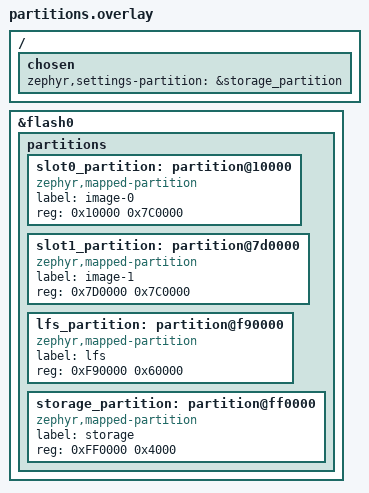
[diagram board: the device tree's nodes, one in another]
/*
 * Flash partition layout — SHARED by the app image and MCUboot.
 *
 * Fed to BOTH images (app via EXTRA_DTC_OVERLAY_FILE, MCUboot via
 * mcuboot_EXTRA_DTC_OVERLAY_FILE in sysbuild/CMakeLists.txt) so their flash maps
 * are identical — otherwise MCUboot stages/looks for the OTA image at a different
 * address than the app writes it to and OTA silently reverts on reboot.
 *
 * ESP32-S31: the ROM reserves the first 8 KB, so MCUboot sits at 0x2000 (56 KB,
 * kept from partitions_0x2000_default_16M.dtsi), not at 0x0 as on S3/C-series.
 * slot0 starts at 0x10000 like every other ZephCore ESP32 board; sys_partition
 * is reclaimed. The LP-core slots and coredump are dropped (unused).
 *
 * 16 MB layout: slots 0x10000..0xF90000 (7.75 MB each), lfs 384 KB @0xF90000,
 * storage 16 KB @0xFF0000.
 */
/delete-node/ &sys_partition;
/delete-node/ &slot0_partition;
/delete-node/ &slot1_partition;
/delete-node/ &slot0_lpcore_partition;
/delete-node/ &slot1_lpcore_partition;
/delete-node/ &storage_partition;
/delete-node/ &coredump_partition;

/ {
	chosen {
		zephyr,settings-partition = &storage_partition;
	};
};

&flash0 {
	partitions {
		/* App slots — equal size (swap-mode compatible), slot0 at 0x10000. */
		slot0_partition: partition@10000 {
			compatible = "zephyr,mapped-partition";
			label = "image-0";
			reg = <0x10000 0x7C0000>;
		};
		slot1_partition: partition@7d0000 {
			compatible = "zephyr,mapped-partition";
			label = "image-1";
			reg = <0x7D0000 0x7C0000>;
		};
		/* LittleFS 384KB (identity/prefs/contacts). */
		lfs_partition: partition@f90000 {
			compatible = "zephyr,mapped-partition";
			label = "lfs";
			reg = <0xF90000 0x60000>;
		};
		/* Settings NVS (BLE bonds when BLE arrives). */
		storage_partition: partition@ff0000 {
			compatible = "zephyr,mapped-partition";
			label = "storage";
			reg = <0xFF0000 0x4000>;
		};
	};
};
